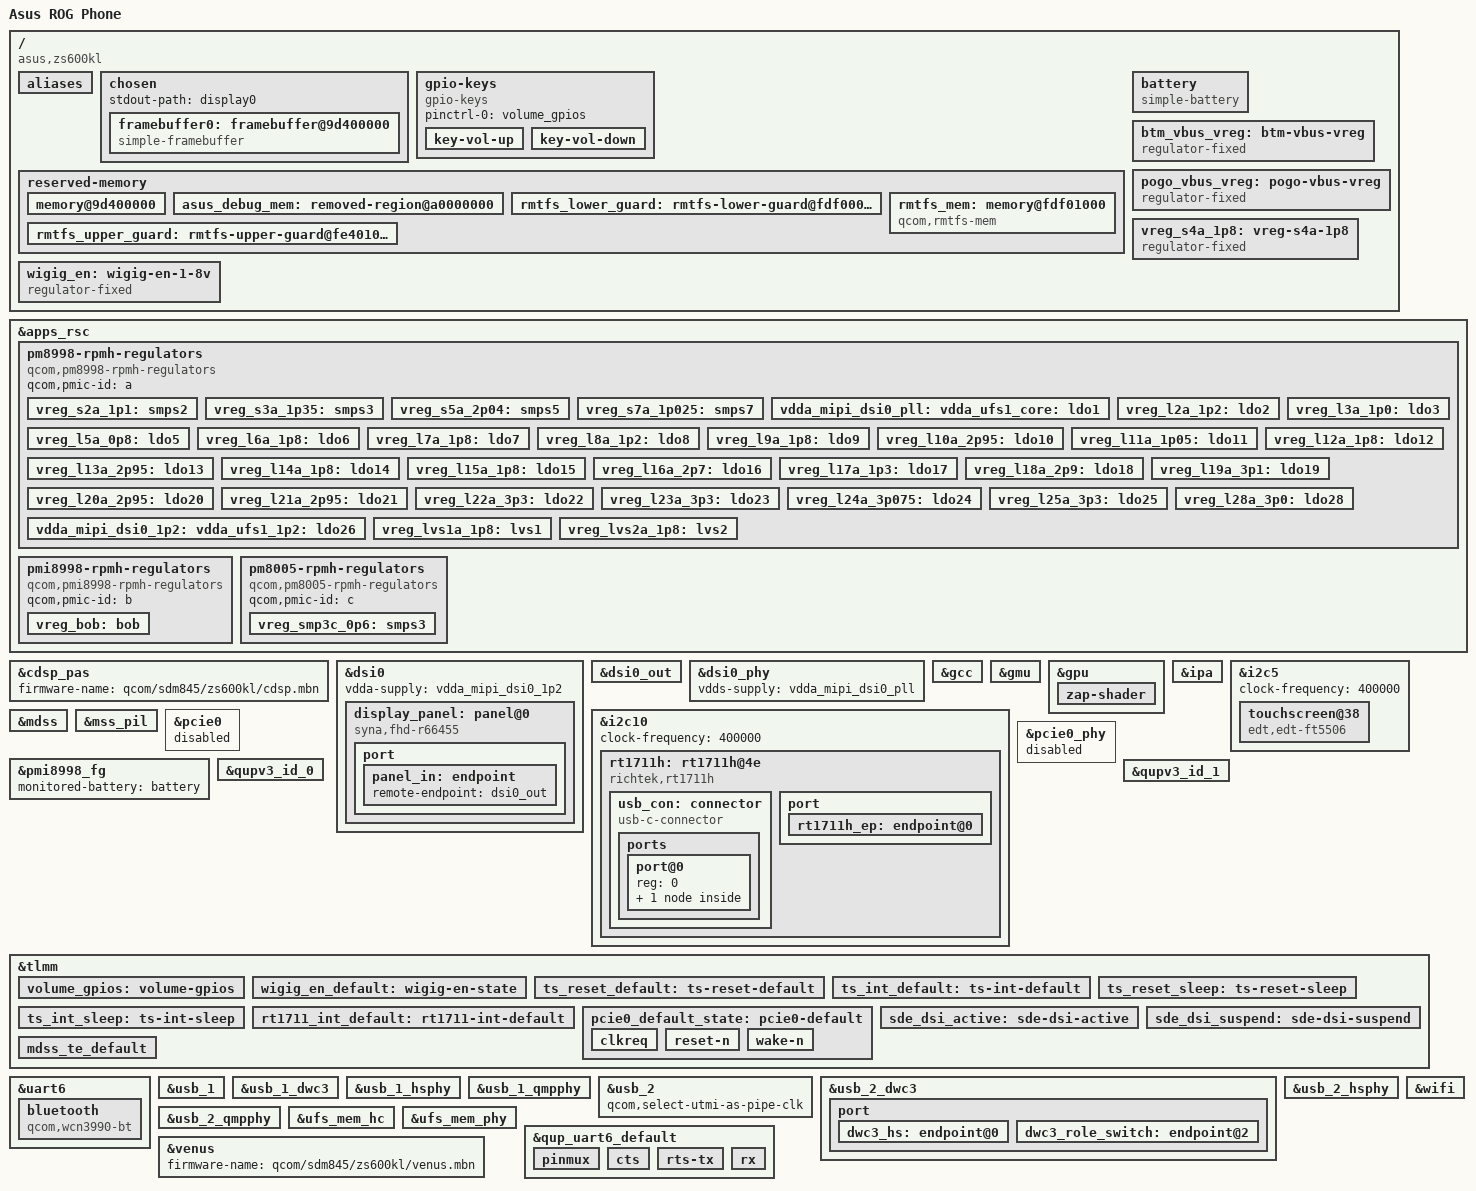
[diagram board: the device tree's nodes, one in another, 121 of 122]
// SPDX-License-Identifier: BSD-3-Clause
/*
 * Copyright (c) 2022, Xilin Wu <strongtz@yeah.net>
 */

/dts-v1/;

#include <dt-bindings/gpio/gpio.h>
#include <dt-bindings/pinctrl/qcom,pmic-gpio.h>
#include <dt-bindings/regulator/qcom,rpmh-regulator.h>
#include <dt-bindings/input/linux-event-codes.h>
#include <dt-bindings/sound/qcom,q6afe.h>
#include <dt-bindings/sound/qcom,q6asm.h>
#include <dt-bindings/usb/pd.h>

/*
 * Asus is using an overclocked Snapdragon 845 SoC on this device, 
 * which has the same frequencies available as the Snapdragon 850
 * used on laptops.
 */
#include "sdm850.dtsi"
#include "pm8998.dtsi"
#include "pmi8998.dtsi"
#include "pm8005.dtsi"

/delete-node/ &rmtfs_mem;

/ {
	model = "Asus ROG Phone";
	compatible = "asus,zs600kl", "qcom,sdm845";
	chassis-type = "handset";

	/* required for bootloader to select correct board */
	qcom,msm-id = <321 0x20000>;
	qcom,board-id = <100 0x0>;

	aliases {
		serial0 = &uart9;
		serial1 = &uart6;
	};

	chosen {
		#address-cells = <2>;
		#size-cells = <2>;
		ranges;

		stdout-path = "display0";

		/* Use framebuffer setup by the bootloader. */
		framebuffer0: framebuffer@9d400000 {
			compatible = "simple-framebuffer";
			reg = <0x0 0x9d400000 0x0 (1080 * 2160 * 4)>;
			width = <1080>;
			height = <2160>;
			stride = <(1080 * 4)>;
			format = "a8r8g8b8";
		};
	};

	gpio-keys {
		compatible = "gpio-keys";

		pinctrl-names = "default";
		pinctrl-0 = <&volume_gpios>;

		key-vol-up {
			autorepeat;
			label = "Volume Up";
			linux,code = <KEY_VOLUMEUP>;
			gpios = <&tlmm 103 GPIO_ACTIVE_LOW>;
			debounce-interval = <15>;
		};

		key-vol-down {
			autorepeat;
			label = "Volume Down";
			linux,code = <KEY_VOLUMEDOWN>;
			gpios = <&tlmm 123 GPIO_ACTIVE_LOW>;
			debounce-interval = <15>;
		};
	};

	reserved-memory {
		/* Framebuffer region */
		memory@9d400000 {
			reg = <0x0 0x9d400000 0x0 0x2400000>;
			no-map;
		};

		asus_debug_mem: removed-region@a0000000 {
			reg = <0x0 0xa0000000 0x0 0x300000>;
			no-map;
		};

		rmtfs_lower_guard: rmtfs-lower-guard@fdf00000 {
			no-map;
			reg = <0x0 0xfdf00000 0x0 0x1000>;
		};

		rmtfs_mem: memory@fdf01000 {
			compatible = "qcom,rmtfs-mem";
			reg = <0x0 0xfdf01000 0x0 0x500000>;
			no-map;

			qcom,client-id = <1>;
			qcom,vmid = <15>;
		};

		rmtfs_upper_guard: rmtfs-upper-guard@fe401000 {
			no-map;
			reg = <0x0 0xfe401000 0x0 0x1000>;
		};
	};

	battery: battery {
		compatible = "simple-battery";

		charge-full-design-microamp-hours = <3800000>;
		voltage-min-design-microvolt = <3400000>;
		voltage-max-design-microvolt = <4358000>;
	};

	btm_vbus_vreg: btm-vbus-vreg {
		compatible = "regulator-fixed";
		regulator-name = "btm_vbus_vreg";

		regulator-min-microvolt = <5000000>;
		regulator-max-microvolt = <5000000>;

		gpio = <&pm8998_gpio 6 0>;
		enable-active-high;

		regulator-enable-ramp-delay = <4000>;
	};

	/* pmi8998 otg function is not used */
	pogo_vbus_vreg: pogo-vbus-vreg {
		compatible = "regulator-fixed";
		regulator-name = "pogo_vbus_vreg";

		regulator-min-microvolt = <5000000>;
		regulator-max-microvolt = <5000000>;

		gpio = <&pmi8998_gpio 11 0>;
		regulator-always-on;
		regulator-boot-on;
		enable-active-high;

		regulator-enable-ramp-delay = <4000>;
	};

	vreg_s4a_1p8: vreg-s4a-1p8 {
		compatible = "regulator-fixed";
		regulator-name = "vreg_s4a_1p8";

		regulator-min-microvolt = <1800000>;
		regulator-max-microvolt = <1800000>;
		regulator-always-on;
	};

	/* WIGIG_EN pin defined as a fixed regulator */
	wigig_en: wigig-en-1-8v {
		compatible = "regulator-fixed";
		regulator-name = "wigig-en-regulator";
		regulator-min-microvolt = <1800000>;
		regulator-max-microvolt = <1800000>;

		gpio = <&tlmm 39 GPIO_ACTIVE_HIGH>;
		enable-active-high;
		pinctrl-names = "default";
		pinctrl-0 = <&wigig_en_default>;
	};

	// pmi8998_tcpm: pmic-tcpm {
	// 	compatible = "qcom,pmi8998-tcpm";

	// 	#address-cells = <1>;
	// 	#size-cells = <0>;

	// 	pmic_tcpm_typec = <&pmi8998_typec>;
	// 	pmic_tcpm_pdphy = <&pmi8998_pdphy>;

	// 	connector {
	// 		compatible = "usb-c-connector";

	// 		power-role = "source";
	// 		data-role = "dual";
	// 		self-powered;

	// 		source-pdos = <PDO_FIXED(5000, 3000,
	// 					   PDO_FIXED_DUAL_ROLE |
	// 					   PDO_FIXED_USB_COMM |
	// 					   PDO_FIXED_DATA_SWAP)>;
	// 	};
	// };
};


&apps_rsc {
	pm8998-rpmh-regulators {
		compatible = "qcom,pm8998-rpmh-regulators";
		qcom,pmic-id = "a";

		vreg_s2a_1p1: smps2 {
			regulator-min-microvolt = <1100000>;
			regulator-max-microvolt = <1100000>;
		};

		vreg_s3a_1p35: smps3 {
			regulator-min-microvolt = <1352000>;
			regulator-max-microvolt = <1352000>;
		};

		vreg_s5a_2p04: smps5 {
			regulator-min-microvolt = <1904000>;
			regulator-max-microvolt = <2040000>;
		};

		vreg_s7a_1p025: smps7 {
			regulator-min-microvolt = <900000>;
			regulator-max-microvolt = <1028000>;
		};

		vdda_mipi_dsi0_pll:
		vdda_ufs1_core:
		vreg_l1a_0p875: ldo1 {
			regulator-min-microvolt = <880000>;
			regulator-max-microvolt = <880000>;
			regulator-initial-mode = <RPMH_REGULATOR_MODE_HPM>;
		};

		vreg_l2a_1p2: ldo2 {
			regulator-min-microvolt = <1200000>;
			regulator-max-microvolt = <1200000>;
			regulator-initial-mode = <RPMH_REGULATOR_MODE_HPM>;
			regulator-always-on;
		};

		vreg_l3a_1p0: ldo3 {
			regulator-min-microvolt = <1000000>;
			regulator-max-microvolt = <1000000>;
			regulator-initial-mode = <RPMH_REGULATOR_MODE_HPM>;
		};

		vreg_l5a_0p8: ldo5 {
			regulator-min-microvolt = <800000>;
			regulator-max-microvolt = <800000>;
			regulator-initial-mode = <RPMH_REGULATOR_MODE_HPM>;

			/* Required by wil6210 - vddio-supply */
			regulator-always-on;
		};

		vreg_l6a_1p8: ldo6 {
			regulator-min-microvolt = <1856000>;
			regulator-max-microvolt = <1856000>;
			regulator-initial-mode = <RPMH_REGULATOR_MODE_HPM>;
		};

		vreg_l7a_1p8: ldo7 {
			regulator-min-microvolt = <1800000>;
			regulator-max-microvolt = <1800000>;
			regulator-initial-mode = <RPMH_REGULATOR_MODE_HPM>;

			/* Required by wil6210 - vdd-supply */
			regulator-always-on;
		};

		vreg_l8a_1p2: ldo8 {
			regulator-min-microvolt = <1200000>;
			regulator-max-microvolt = <1248000>;
			regulator-initial-mode = <RPMH_REGULATOR_MODE_HPM>;
		};

		vreg_l9a_1p8: ldo9 {
			regulator-min-microvolt = <1704000>;
			regulator-max-microvolt = <2928000>;
			regulator-initial-mode = <RPMH_REGULATOR_MODE_HPM>;
		};

		vreg_l10a_2p95: ldo10 {
			regulator-min-microvolt = <1704000>;
			regulator-max-microvolt = <2928000>;
			regulator-initial-mode = <RPMH_REGULATOR_MODE_HPM>;
		};

		vreg_l11a_1p05: ldo11 {
			regulator-min-microvolt = <1000000>;
			regulator-max-microvolt = <1048000>;
			regulator-initial-mode = <RPMH_REGULATOR_MODE_HPM>;
		};

		vreg_l12a_1p8: ldo12 {
			regulator-min-microvolt = <1800000>;
			regulator-max-microvolt = <1800000>;
			regulator-initial-mode = <RPMH_REGULATOR_MODE_HPM>;
		};

		vreg_l13a_2p95: ldo13 {
			regulator-min-microvolt = <1800000>;
			regulator-max-microvolt = <2960000>;
			regulator-initial-mode = <RPMH_REGULATOR_MODE_HPM>;
		};

		vreg_l14a_1p8: ldo14 {
			regulator-min-microvolt = <1800000>;
			regulator-max-microvolt = <1880000>;
			regulator-initial-mode = <RPMH_REGULATOR_MODE_HPM>;
			regulator-always-on;
		};

		vreg_l15a_1p8: ldo15 {
			regulator-min-microvolt = <1800000>;
			regulator-max-microvolt = <1800000>;
			regulator-initial-mode = <RPMH_REGULATOR_MODE_HPM>;
		};

		vreg_l16a_2p7: ldo16 {
			regulator-min-microvolt = <2704000>;
			regulator-max-microvolt = <2704000>;
			regulator-initial-mode = <RPMH_REGULATOR_MODE_HPM>;
		};

		vreg_l17a_1p3: ldo17 {
			regulator-min-microvolt = <1304000>;
			regulator-max-microvolt = <1304000>;
			regulator-initial-mode = <RPMH_REGULATOR_MODE_HPM>;
			regulator-always-on;
		};

		vreg_l18a_2p9: ldo18 {
			regulator-min-microvolt = <2704000>;
			regulator-max-microvolt = <2960000>;
			regulator-initial-mode = <RPMH_REGULATOR_MODE_HPM>;
		};

		vreg_l19a_3p1: ldo19 {
			regulator-min-microvolt = <2856000>;
			regulator-max-microvolt = <3104000>;
			regulator-initial-mode = <RPMH_REGULATOR_MODE_HPM>;
		};

		vreg_l20a_2p95: ldo20 {
			regulator-min-microvolt = <2704000>;
			regulator-max-microvolt = <2960000>;
			regulator-initial-mode = <RPMH_REGULATOR_MODE_HPM>;
		};

		vreg_l21a_2p95: ldo21 {
			regulator-min-microvolt = <2704000>;
			regulator-max-microvolt = <2960000>;
			regulator-initial-mode = <RPMH_REGULATOR_MODE_HPM>;
		};

		vreg_l22a_3p3: ldo22 {
			regulator-min-microvolt = <2864000>;
			regulator-max-microvolt = <3312000>;
			regulator-initial-mode = <RPMH_REGULATOR_MODE_HPM>;
		};

		vreg_l23a_3p3: ldo23 {
			regulator-min-microvolt = <3000000>;
			regulator-max-microvolt = <3312000>;
			regulator-initial-mode = <RPMH_REGULATOR_MODE_HPM>;
		};

		vreg_l24a_3p075: ldo24 {
			regulator-min-microvolt = <3088000>;
			regulator-max-microvolt = <3088000>;
			regulator-initial-mode = <RPMH_REGULATOR_MODE_HPM>;
		};

		vreg_l25a_3p3: ldo25 {
			regulator-min-microvolt = <3000000>;
			regulator-max-microvolt = <3312000>;
			regulator-initial-mode = <RPMH_REGULATOR_MODE_HPM>;
			regulator-always-on;
		};

		vdda_mipi_dsi0_1p2:
		vdda_ufs1_1p2:
		vreg_l26a_1p2: ldo26 {
			regulator-min-microvolt = <1200000>;
			regulator-max-microvolt = <1200000>;
			regulator-initial-mode = <RPMH_REGULATOR_MODE_HPM>;
		};

		vreg_l28a_3p0: ldo28 {
			regulator-min-microvolt = <2856000>;
			regulator-max-microvolt = <3008000>;
			regulator-initial-mode = <RPMH_REGULATOR_MODE_HPM>;
			regulator-always-on;
		};

		vreg_lvs1a_1p8: lvs1 {
			regulator-min-microvolt = <1800000>;
			regulator-max-microvolt = <1800000>;
		};

		vreg_lvs2a_1p8: lvs2 {
			regulator-min-microvolt = <1800000>;
			regulator-max-microvolt = <1800000>;
		};
	};

	pmi8998-rpmh-regulators {
		compatible = "qcom,pmi8998-rpmh-regulators";
		qcom,pmic-id = "b";

		vreg_bob: bob {
			regulator-min-microvolt = <3312000>;
			regulator-max-microvolt = <3600000>;
			regulator-initial-mode = <RPMH_REGULATOR_MODE_AUTO>;
			regulator-allow-bypass;
		};
	};

	pm8005-rpmh-regulators {
		compatible = "qcom,pm8005-rpmh-regulators";
		qcom,pmic-id = "c";

		vreg_smp3c_0p6: smps3 {
			regulator-min-microvolt = <600000>;
			regulator-max-microvolt = <600000>;
			regulator-always-on;
		};
	};
};


&cdsp_pas {
	firmware-name = "qcom/sdm845/zs600kl/cdsp.mbn";
	status = "okay";
};


&dsi0 {
	vdda-supply = <&vdda_mipi_dsi0_1p2>;
	status = "okay";

	display_panel: panel@0 {
		compatible = "syna,fhd-r66455";
		#address-cells = <1>;
		#size-cells = <0>;
		reg = <0>;

		reset-gpios = <&tlmm 6 GPIO_ACTIVE_LOW>;
		disp-te-gpios = <&tlmm 10 GPIO_ACTIVE_LOW>;
		vddio-supply = <&vreg_l14a_1p8>;
		vci-supply = <&vreg_l28a_3p0>;

		pinctrl-names = "default", "sleep";
		pinctrl-0 = <&sde_dsi_active &mdss_te_default>;
		pinctrl-1 = <&sde_dsi_suspend>;

		port {
			panel_in: endpoint {
				remote-endpoint = <&dsi0_out>;
			};
		};
	};
};


&dsi0_out {
	remote-endpoint = <&panel_in>;
	data-lanes = <0 1 2 3>;
};

&dsi0_phy {
	vdds-supply = <&vdda_mipi_dsi0_pll>;
	status = "okay";
};


&gcc {
	protected-clocks = <GCC_QSPI_CORE_CLK>,
				<GCC_QSPI_CORE_CLK_SRC>,
				<GCC_QSPI_CNOC_PERIPH_AHB_CLK>,
				<GCC_LPASS_Q6_AXI_CLK>,
				<GCC_LPASS_SWAY_CLK>;
};

&gmu {
	status = "okay";
};

&gpu {
	status = "okay";

	zap-shader {
		memory-region = <&gpu_mem>;
		firmware-name = "qcom/sdm845/zs600kl/a630_zap.mbn";
	};
};

&ipa {
	memory-region = <&ipa_fw_mem>;
	firmware-name = "qcom/sdm845/zs600kl/ipa_fws.mbn";
	status = "okay";
};

&i2c5 {
	clock-frequency = <400000>;
	status = "okay";

	touchscreen@38 {
		compatible = "edt,edt-ft5506";
		reg = <0x38>;

		interrupt-parent = <&tlmm>;
		interrupts = <125 0x2008>;

		reset-gpios = <&tlmm 99 GPIO_ACTIVE_LOW>;

		touchscreen-size-x = <1080>;
		touchscreen-size-y = <2160>;

		pinctrl-names = "default", "sleep";
		pinctrl-0 = <&ts_int_default &ts_reset_default>;
		pinctrl-1 = <&ts_int_sleep &ts_reset_sleep>;
	};
};

&i2c10 {
	clock-frequency = <400000>;
	status = "okay";

	rt1711h: rt1711h@4e {
		compatible = "richtek,rt1711h";
		reg = <0x4e>;
		interrupt-parent = <&tlmm>;
		interrupts = <118 IRQ_TYPE_LEVEL_LOW>;
		pinctrl-names = "default";
		pinctrl-0 = <&rt1711_int_default>;

		usb_con: connector {
			compatible = "usb-c-connector";
			label = "USB-C";
			data-role = "dual";
			power-role = "dual";
			try-power-role = "sink";
			typec-power-opmode = "default";
			source-pdos = <PDO_FIXED(5000, 1500, PDO_FIXED_USB_COMM)>;
			sink-pdos = <PDO_FIXED(5000, 500, PDO_FIXED_USB_COMM)
				PDO_VAR(5000, 5000, 1000)>;
			op-sink-microwatt = <10000000>;
			vbus-supply = <&btm_vbus_vreg>;

			ports {
				#address-cells = <1>;
				#size-cells = <0>;

				port@0 {
					reg = <0>;
					usb_con_hs: endpoint {
						remote-endpoint = <&dwc3_hs>;
					};
				};
			};
		};
		port {
			#address-cells = <1>;
			#size-cells = <0>;

			rt1711h_ep: endpoint@0 {
				reg = <0>;
				remote-endpoint = <&dwc3_role_switch>;
			};
		};
	};
};

&mdss {
	status = "okay";
};

&mss_pil {
	firmware-name = "qcom/sdm845/zs600kl/mba.mbn", "qcom/sdm845/zs600kl/modem.mbn";
	status = "okay";
};

/* FIXME: wil6210 crashes the system while loading firmware */
&pcie0 {
	status = "disabled";
	perst-gpio = <&tlmm 35 GPIO_ACTIVE_LOW>;

	vddpe-3v3-supply = <&wigig_en>;

	pinctrl-names = "default";
	pinctrl-0 = <&pcie0_default_state>;
};

&pcie0_phy {
	status = "disabled";

	vdda-phy-supply = <&vreg_l1a_0p875>;
	vdda-pll-supply = <&vreg_l26a_1p2>;
};

&pmi8998_fg {
	status = "okay";
	monitored-battery = <&battery>;
};

// &q6afedai {
// 	qi2s@22 {
// 		reg = <22>;
// 		qcom,sd-lines = <0>;
// 	};
// };

// &q6asmdai {
// 	dai@0 {
// 		reg = <0>;
// 	};

// 	dai@1 {
// 		reg = <1>;
// 	};

// 	dai@2 {
// 		reg = <2>;
// 	};
// };

&qupv3_id_0 {
	status = "okay";
};

&qupv3_id_1 {
	status = "okay";
};

// &qup_i2c14_default {
// 	pinconf {
// 		pins = "gpio33", "gpio34";
// 		drive-strength = <2>;
// 		bias-disable;
// 	};
// };

&tlmm {
	// 6 10 35~37 39 45~48 55~56 85~86 99 103 118 123 125
	gpio-reserved-ranges = <0 6>, <7 3>, <11 24>, <38 1>, <40 5>, <49 6>, <57 28>, <87 12>, <100 3>, <104 14>, <119 4>, <124 1>, <126 24>;

	volume_gpios: volume-gpios {
		pins = "gpio103", "gpio123";
		function = "gpio";
		drive-strength = <2>;
		bias-pull-up;
	};

	wigig_en_default: wigig-en-state {
		pins = "gpio39";
		function = "gpio";
		output-low;
		drive-strength = <2>;
		bias-disable;
	};

	ts_reset_default: ts-reset-default {
		pins = "gpio99";
		function = "gpio";
		bias-pull-up;
		drive-strength = <8>;
	};

	ts_int_default: ts-int-default {
		pins = "gpio125";
		function = "gpio";
		bias-disable;
		drive-strength = <8>;
		input-enable;
	};

	ts_reset_sleep: ts-reset-sleep {
		pins = "gpio99";
		function = "gpio";
		bias-pull-down;
		drive-strength = <2>;
	};

	ts_int_sleep: ts-int-sleep {
		pins = "gpio125";
		function = "gpio";
		bias-disable;
		drive-strength = <2>;
		input-enable;
	};

	rt1711_int_default: rt1711-int-default {
		pins = "gpio118";
		function = "gpio";
		drive-strength = <2>;
		bias-pull-up;
	};

	pcie0_default_state: pcie0-default {
		clkreq {
			pins = "gpio36";
			function = "pci_e0";
			bias-pull-up;
		};

		reset-n {
			pins = "gpio35";
			function = "gpio";

			drive-strength = <2>;
			output-low;
			bias-pull-down;
		};

		wake-n {
			pins = "gpio37";
			function = "gpio";

			drive-strength = <2>;
			bias-pull-up;
		};
	};

	sde_dsi_active: sde-dsi-active {
		pins = "gpio6";
		function = "gpio";
		drive-strength = <8>;
		bias-disable = <0>;
	};

	sde_dsi_suspend: sde-dsi-suspend {
		pins = "gpio6";
		function = "gpio";
		drive-strength = <2>;
		bias-pull-down;
	};

	mdss_te_default: mdss_te_default {
		pins = "gpio10";
		function = "mdp_vsync";
		drive-strength = <2>;
		bias-pull-down;
	};

	// wcd_intr_default: wcd-intr-default {
	// 	pins = "gpio54";
	// 	function = "gpio";
	// 	input-enable;
	// 	bias-pull-down;
	// 	drive-strength = <2>;
	// };
};

&uart6 {
	status = "okay";

	bluetooth {
		compatible = "qcom,wcn3990-bt";

		/* This path is relative to the qca/ subdir under lib/firmware. */
		firmware-name = "zs600kl/crnv21.bin";

		vddio-supply = <&vreg_s4a_1p8>;
		vddxo-supply = <&vreg_l7a_1p8>;
		vddrf-supply = <&vreg_l17a_1p3>;
		vddch0-supply = <&vreg_l25a_3p3>;
		max-speed = <3200000>;
	};
};

&usb_1 {
	status = "okay";
};

&usb_1_dwc3 {
	dr_mode = "peripheral";
	tx-fifo-resize;
	snps,has-lpm-erratum;
	snps,hird-threshold = /bits/ 8 <0x10>;
	snps,usb3_lpm_capable;
	// workaround for USB timeout issue
	snps,usb2-lpm-disable;
};

&usb_1_hsphy {
	vdda-phy-dpdm-supply = <&vreg_l24a_3p075>;
	vdda-pll-supply = <&vreg_l12a_1p8>;
	vdd-supply = <&vreg_l1a_0p875>;

	qcom,imp-res-offset-value = <0>;
	qcom,bias-ctrl-value = <0x11>;
	qcom,hstx-trim-value = <QUSB2_V2_HSTX_TRIM_24_0_MA>;
	qcom,preemphasis-level = <QUSB2_V2_PREEMPHASIS_15_PERCENT>;
	qcom,preemphasis-width = <QUSB2_V2_PREEMPHASIS_WIDTH_HALF_BIT>;
	qcom,hsdisc-trim-value = <3>;

	status = "okay";
};

&usb_1_qmpphy {
	vdda-pll-supply = <&vreg_l1a_0p875>;
	vdda-phy-supply = <&vreg_l26a_1p2>;
	status = "okay";
};

&usb_2 {
	/* We'll use this as USB 2.0 only */
	qcom,select-utmi-as-pipe-clk;
	status = "okay";
};

&usb_2_dwc3 {
	dr_mode = "otg";
	usb-role-switch;
	role-switch-default-mode = "host";

	tx-fifo-resize;
	snps,has-lpm-erratum;
	snps,hird-threshold = /bits/ 8 <0x10>;
	snps,usb3_lpm_capable;
	// workaround for USB timeout issue
	snps,usb2-lpm-disable;

	/* Fastest mode for USB 2 */
	maximum-speed = "high-speed";

	/* Remove USB3 phy */
	phys = <&usb_2_hsphy>;
	phy-names = "usb2-phy";

	port {
		#address-cells = <1>;
		#size-cells = <0>;

		dwc3_hs: endpoint@0 {
			reg = <0>;
			remote-endpoint = <&usb_con_hs>;
		};

		dwc3_role_switch: endpoint@2 {
			reg = <2>;
			remote-endpoint = <&rt1711h_ep>;
		};
	};
};

&usb_2_hsphy {
	status = "okay";

	vdd-supply = <&vreg_l1a_0p875>;
	vdda-pll-supply = <&vreg_l12a_1p8>;
	vdda-phy-dpdm-supply = <&vreg_l24a_3p075>;

	qcom,imp-res-offset-value = <0>;
	qcom,bias-ctrl-value = <0x10>;
	qcom,hstx-trim-value = <QUSB2_V2_HSTX_TRIM_24_0_MA>;
	qcom,preemphasis-level = <QUSB2_V2_PREEMPHASIS_15_PERCENT>;
	qcom,preemphasis-width = <QUSB2_V2_PREEMPHASIS_WIDTH_HALF_BIT>;
	qcom,hsdisc-trim-value = <3>;
};

&usb_2_qmpphy {
	status = "okay";

	vdda-phy-supply = <&vreg_l26a_1p2>;
	vdda-pll-supply = <&vreg_l1a_0p875>;
};

&ufs_mem_hc {
	reset-gpios = <&tlmm 150 GPIO_ACTIVE_LOW>;
	vcc-supply = <&vreg_l20a_2p95>;
	vccq2-supply = <&vreg_s4a_1p8>;
	vcc-max-microamp = <800000>;
	vccq2-max-microamp = <800000>;
	status = "okay";
};

&ufs_mem_phy {
	vdda-phy-supply = <&vdda_ufs1_core>;
	vdda-pll-supply = <&vdda_ufs1_1p2>;
	status = "okay";
};

&venus {
	firmware-name = "qcom/sdm845/zs600kl/venus.mbn";
	status = "okay";
};

// &wcd9340 {
// 	pinctrl-0 = <&wcd_intr_default>;
// 	pinctrl-names = "default";
// 	clock-names = "extclk";
// 	clocks = <&rpmhcc RPMH_LN_BB_CLK2>;
// 	reset-gpios = <&tlmm 64 0>;
// 	vdd-buck-sido-supply = <&vreg_s4a_1p8>;
// 	vdd-buck-supply = <&vreg_s4a_1p8>;
// 	vdd-tx-supply = <&vreg_s4a_1p8>;
// 	vdd-rx-supply = <&vreg_s4a_1p8>;
// 	vdd-io-supply = <&vreg_s4a_1p8>;

// 	qcom,micbias1-microvolt = <2700000>;
// 	qcom,micbias2-microvolt = <1800000>;
// 	qcom,micbias3-microvolt = <2700000>;
// 	qcom,micbias4-microvolt = <2700000>;
// };

&wifi {
	vdd-0.8-cx-mx-supply = <&vreg_l5a_0p8>;
	vdd-1.8-xo-supply = <&vreg_l7a_1p8>;
	vdd-1.3-rfa-supply = <&vreg_l17a_1p3>;
	vdd-3.3-ch0-supply = <&vreg_l25a_3p3>;
	vdd-3.3-ch1-supply = <&vreg_l23a_3p3>;

	qcom,snoc-host-cap-skip-quirk;
	status = "okay";
};

/* PINCTRL - additions to nodes defined in sdm845.dtsi */

&qup_uart6_default {
	pinmux {
		 pins = "gpio45", "gpio46", "gpio47", "gpio48";
		 function = "qup6";
	};

	cts {
		pins = "gpio45";
		bias-disable;
	};

	rts-tx {
		pins = "gpio46", "gpio47";
		drive-strength = <2>;
		bias-disable;
	};

	rx {
		pins = "gpio48";
		bias-pull-up;
	};
};
